AUTOSAR XML (schema 4-2-2)
package /ComponentTypes
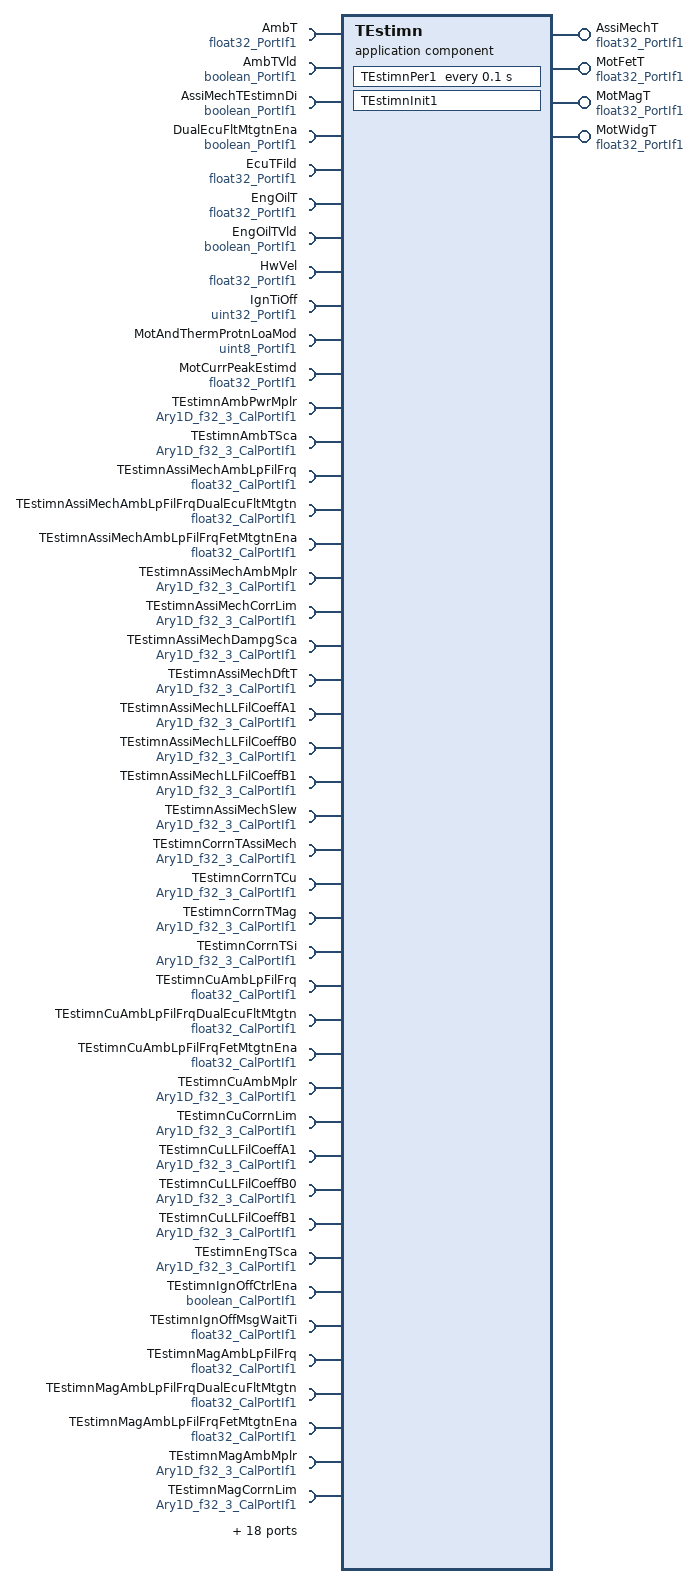
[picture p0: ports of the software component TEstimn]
  application sw component type TEstimn
    4 x provide port, all with nonqueued-sender-com-spec{data-element=Val, init-value=25}, provided-interface=float32_PortIf1:
      AssiMechT
      MotFetT
      MotMagT
      MotWidgT
    62 x require port:
      AmbT: nonqueued-receiver-com-spec{data-element=Val, filter=data-filter-type=ALWAYS, init-value=0}, required-interface=float32_PortIf1
      AmbTVld: nonqueued-receiver-com-spec{data-element=Logl, filter=data-filter-type=ALWAYS, init-value=0}, required-interface=boolean_PortIf1
      AssiMechTEstimnDi: nonqueued-receiver-com-spec{data-element=Logl, filter=data-filter-type=ALWAYS, init-value=0}, required-interface=boolean_PortIf1
      DualEcuFltMtgtnEna: nonqueued-receiver-com-spec{data-element=Logl, filter=data-filter-type=ALWAYS, init-value=0}, required-interface=boolean_PortIf1
      EcuTFild: nonqueued-receiver-com-spec{data-element=Val, filter=data-filter-type=ALWAYS, init-value=25}, required-interface=float32_PortIf1
      EngOilT: nonqueued-receiver-com-spec{data-element=Val, filter=data-filter-type=ALWAYS, init-value=0}, required-interface=float32_PortIf1
      EngOilTVld: nonqueued-receiver-com-spec{data-element=Logl, filter=data-filter-type=ALWAYS, init-value=0}, required-interface=boolean_PortIf1
      HwVel: nonqueued-receiver-com-spec{data-element=Val, filter=data-filter-type=ALWAYS, init-value=0}, required-interface=float32_PortIf1
      IgnTiOff: nonqueued-receiver-com-spec{data-element=Val, filter=data-filter-type=ALWAYS, init-value=0}, required-interface=uint32_PortIf1
      MotAndThermProtnLoaMod: nonqueued-receiver-com-spec{data-element=Val, filter=data-filter-type=ALWAYS, init-value=0}, required-interface=uint8_PortIf1
      MotCurrPeakEstimd: nonqueued-receiver-com-spec{data-element=Val, filter=data-filter-type=ALWAYS, init-value=0}, required-interface=float32_PortIf1
      TEstimnAmbPwrMplr: parameter-require-com-spec{init-value=[0.01, 0.01, 0.01], parameter=Ary1D}, required-interface=Ary1D_f32_3_CalPortIf1
      TEstimnAmbTSca: parameter-require-com-spec{init-value=[0.9, 0.9, 0.9], parameter=Ary1D}, required-interface=Ary1D_f32_3_CalPortIf1
      TEstimnAssiMechAmbLpFilFrq: parameter-require-com-spec{init-value=0.024, parameter=Val}, required-interface=float32_CalPortIf1
      TEstimnAssiMechAmbLpFilFrqDualEcuFltMtgtn: parameter-require-com-spec{init-value=0.024, parameter=Val}, required-interface=float32_CalPortIf1
      TEstimnAssiMechAmbLpFilFrqFetMtgtnEna: parameter-require-com-spec{init-value=0.024, parameter=Val}, required-interface=float32_CalPortIf1
      TEstimnAssiMechAmbMplr: parameter-require-com-spec{init-value=[0.01, 0.01, 0.01], parameter=Ary1D}, required-interface=Ary1D_f32_3_CalPortIf1
      TEstimnAssiMechCorrLim: parameter-require-com-spec{init-value=[60, 60, 60], parameter=Ary1D}, required-interface=Ary1D_f32_3_CalPortIf1
      TEstimnAssiMechDampgSca: parameter-require-com-spec{init-value=[0.0001, 0.0001, 0.0001], parameter=Ary1D}, required-interface=Ary1D_f32_3_CalPortIf1
      TEstimnAssiMechDftT: parameter-require-com-spec{init-value=[50, 50, 50], parameter=Ary1D}, required-interface=Ary1D_f32_3_CalPortIf1
      TEstimnAssiMechLLFilCoeffA1: parameter-require-com-spec{init-value=[0.99996858, 0.99996858, 0.99996858], parameter=Ary1D}, required-interface=Ary1D_f32_3_CalPortIf1
      TEstimnAssiMechLLFilCoeffB0: parameter-require-com-spec{init-value=[0.4761987, 0.4761987, 0.4761987], parameter=Ary1D}, required-interface=Ary1D_f32_3_CalPortIf1
      TEstimnAssiMechLLFilCoeffB1: parameter-require-com-spec{init-value=[-0.4761673, -0.4761673, -0.4761673], parameter=Ary1D}, required-interface=Ary1D_f32_3_CalPortIf1
      TEstimnAssiMechSlew: parameter-require-com-spec{init-value=[1, 1, 1], parameter=Ary1D}, required-interface=Ary1D_f32_3_CalPortIf1
      TEstimnCorrnTAssiMech: parameter-require-com-spec{init-value=[0, 0, 0], parameter=Ary1D}, required-interface=Ary1D_f32_3_CalPortIf1
      TEstimnCorrnTCu: parameter-require-com-spec{init-value=[0, 0, 0], parameter=Ary1D}, required-interface=Ary1D_f32_3_CalPortIf1
      TEstimnCorrnTMag: parameter-require-com-spec{init-value=[0, 0, 0], parameter=Ary1D}, required-interface=Ary1D_f32_3_CalPortIf1
      TEstimnCorrnTSi: parameter-require-com-spec{init-value=[0, 0, 0], parameter=Ary1D}, required-interface=Ary1D_f32_3_CalPortIf1
      TEstimnCuAmbLpFilFrq: parameter-require-com-spec{init-value=0.024, parameter=Val}, required-interface=float32_CalPortIf1
      TEstimnCuAmbLpFilFrqDualEcuFltMtgtn: parameter-require-com-spec{init-value=0.024, parameter=Val}, required-interface=float32_CalPortIf1
      TEstimnCuAmbLpFilFrqFetMtgtnEna: parameter-require-com-spec{init-value=0.024, parameter=Val}, required-interface=float32_CalPortIf1
      TEstimnCuAmbMplr: parameter-require-com-spec{init-value=[0.75, 0.75, 0.75], parameter=Ary1D}, required-interface=Ary1D_f32_3_CalPortIf1
      TEstimnCuCorrnLim: parameter-require-com-spec{init-value=[80, 80, 80], parameter=Ary1D}, required-interface=Ary1D_f32_3_CalPortIf1
      TEstimnCuLLFilCoeffA1: parameter-require-com-spec{init-value=[0.999943, 0.999943, 0.999943], parameter=Ary1D}, required-interface=Ary1D_f32_3_CalPortIf1
      TEstimnCuLLFilCoeffB0: parameter-require-com-spec{init-value=[0.86667, 0.86667, 0.86667], parameter=Ary1D}, required-interface=Ary1D_f32_3_CalPortIf1
      TEstimnCuLLFilCoeffB1: parameter-require-com-spec{init-value=[-0.866613, -0.866613, -0.866613], parameter=Ary1D}, required-interface=Ary1D_f32_3_CalPortIf1
      TEstimnEngTSca: parameter-require-com-spec{init-value=[0.1, 0.1, 0.1], parameter=Ary1D}, required-interface=Ary1D_f32_3_CalPortIf1
      TEstimnIgnOffCtrlEna: parameter-require-com-spec{init-value=0, parameter=Logl}, required-interface=boolean_CalPortIf1
      TEstimnIgnOffMsgWaitTi: parameter-require-com-spec{init-value=0.5, parameter=Val}, required-interface=float32_CalPortIf1
      TEstimnMagAmbLpFilFrq: parameter-require-com-spec{init-value=0.024, parameter=Val}, required-interface=float32_CalPortIf1
      TEstimnMagAmbLpFilFrqDualEcuFltMtgtn: parameter-require-com-spec{init-value=0.024, parameter=Val}, required-interface=float32_CalPortIf1
      TEstimnMagAmbLpFilFrqFetMtgtnEna: parameter-require-com-spec{init-value=0.024, parameter=Val}, required-interface=float32_CalPortIf1
      TEstimnMagAmbMplr: parameter-require-com-spec{init-value=[0.01, 0.01, 0.01], parameter=Ary1D}, required-interface=Ary1D_f32_3_CalPortIf1
      TEstimnMagCorrnLim: parameter-require-com-spec{init-value=[60, 60, 60], parameter=Ary1D}, required-interface=Ary1D_f32_3_CalPortIf1
      TEstimnMagLLFilCoeffA1: parameter-require-com-spec{init-value=[0.999962, 0.999962, 0.999962], parameter=Ary1D}, required-interface=Ary1D_f32_3_CalPortIf1
      TEstimnMagLLFilCoeffB0: parameter-require-com-spec{init-value=[0.571437, 0.571437, 0.571437], parameter=Ary1D}, required-interface=Ary1D_f32_3_CalPortIf1
      TEstimnMagLLFilCoeffB1: parameter-require-com-spec{init-value=[-0.571399, -0.571399, -0.571399], parameter=Ary1D}, required-interface=Ary1D_f32_3_CalPortIf1
      TEstimnSiAmbLpFilFrq: parameter-require-com-spec{init-value=0.024, parameter=Val}, required-interface=float32_CalPortIf1
      TEstimnSiAmbLpFilFrqDualEcuFltMtgtn: parameter-require-com-spec{init-value=0.024, parameter=Val}, required-interface=float32_CalPortIf1
      TEstimnSiAmbLpFilFrqFetMtgtnEna: parameter-require-com-spec{init-value=0.024, parameter=Val}, required-interface=float32_CalPortIf1
      TEstimnSiAmbMplr: parameter-require-com-spec{init-value=[0, 0, 0], parameter=Ary1D}, required-interface=Ary1D_f32_3_CalPortIf1
      TEstimnSiCorrnLim: parameter-require-com-spec{init-value=[60, 60, 60], parameter=Ary1D}, required-interface=Ary1D_f32_3_CalPortIf1
      TEstimnSiLLFilCoeffA1: parameter-require-com-spec{init-value=[0.999889, 0.999889, 0.999889], parameter=Ary1D}, required-interface=Ary1D_f32_3_CalPortIf1
      TEstimnSiLLFilCoeffB0: parameter-require-com-spec{init-value=[1.68568, 1.68568, 1.68568], parameter=Ary1D}, required-interface=Ary1D_f32_3_CalPortIf1
      TEstimnSiLLFilCoeffB1: parameter-require-com-spec{init-value=[-1.68556, -1.68556, -1.68556], parameter=Ary1D}, required-interface=Ary1D_f32_3_CalPortIf1
      TEstimnTauAssiMech: parameter-require-com-spec{init-value=[4000, 4000, 4000], parameter=Ary1D}, required-interface=Ary1D_f32_3_CalPortIf1
      TEstimnTauCu: parameter-require-com-spec{init-value=[79, 79, 79], parameter=Ary1D}, required-interface=Ary1D_f32_3_CalPortIf1
      TEstimnTauMag: parameter-require-com-spec{init-value=[50, 50, 50], parameter=Ary1D}, required-interface=Ary1D_f32_3_CalPortIf1
      TEstimnTauSi: parameter-require-com-spec{init-value=[214, 214, 214], parameter=Ary1D}, required-interface=Ary1D_f32_3_CalPortIf1
      TEstimnWghtAvrgTDi: parameter-require-com-spec{init-value=[0, 0, 0], parameter=Ary1D}, required-interface=Ary1D_logl_3_CalPortIf1
      TFilStVal: required-com-specs=[EraseBlock, GetErrorStatus, InvalidateNvBlock, ReadBlock, SetRamBlockStatus, WriteBlock], required-interface=NvMService_AC3_SRBS
      VehTiVld: nonqueued-receiver-com-spec{data-element=Logl, filter=data-filter-type=ALWAYS, init-value=0}, required-interface=boolean_PortIf1
    behavior TEstimn_InternalBehavior
      ar-typed-per-instance-memorys:
        36 x data, all with sw-calibration-access=READ-ONLY:
          AmbTVldPrev: type=boolean
          AssiMechFilLp: type=FilLpRec1
          AssiMechTEstimnPrev: type=float32
          AssiMechTInitEna: type=boolean
          AssiMechTSlewLimPrev: type=float32
          CuFilLp: type=FilLpRec1
          CuTEstimnPrev: type=float32
          dTEstimnAmbPwr: type=float32
          dTEstimnAssiMechCorrn: type=float32
          dTEstimnAssiMechDampgSca: type=float32
          dTEstimnAssiMechFil: type=float32
          dTEstimnCuCorrn: type=float32
          dTEstimnMagCorrn: type=float32
          dTEstimnScadAmbT: type=float32
          dTEstimnScadEngT: type=float32
          dTEstimnSiCorrn: type=float32
          dTEstimnWghtAvrgT: type=float32
          DualEcuFltMtgtnPrev: type=boolean
          EngOilTVldPrev: type=boolean
          FetMtgtnEnaPrev: type=boolean
          FilAssiMechLLValPwrUp: type=float32
          FilAssiMechLpValPwrUp: type=float32
          FilCuLLValPwrUp: type=float32
          FilCuLpValPwrUp: type=float32
          FilMagLLValPwrUp: type=float32
          FilMagLpValPwrUp: type=float32
          FilSiLLValPwrUp: type=float32
          FilSiLpValPwrUp: type=float32
          MagFilLp: type=FilLpRec1
          MagTEstimnPrev: type=float32
          RepInitCntrFlg: type=boolean
          RepInitCntrVal: type=float32
          SiFilLp: type=FilLpRec1
          SiTEstimnPrev: type=float32
          TEstimnFltMtgtnCalIdx: type=uint8
          TFilStVal: type=TFilStValRec1
      init event TEstimn_InitEvent: start-on-event=TEstimnInit1
      timing event TMT_TEstimnPer1: start-on-event=TEstimnPer1, period=0.1
      explicit-inter-runnable-variables:
        data FilStVariRepInitFlg: type=boolean, init-value=0
      runnable TEstimnInit1
        data-receive-point-by-arguments:
          9 x access:
            REC_AmbT_Val: accessed-variable=AmbT.Val
            REC_AmbTVld_Logl: accessed-variable=AmbTVld.Logl
            REC_DualEcuFltMtgtnEna_Logl: accessed-variable=DualEcuFltMtgtnEna.Logl
            REC_EcuTFild_Val: accessed-variable=EcuTFild.Val
            REC_EngOilT_Val: accessed-variable=EngOilT.Val
            REC_EngOilTVld_Logl: accessed-variable=EngOilTVld.Logl
            REC_IgnTiOff_Val: accessed-variable=IgnTiOff.Val
            REC_MotAndThermProtnLoaMod_Val: accessed-variable=MotAndThermProtnLoaMod.Val
            REC_VehTiVld_Logl: accessed-variable=VehTiVld.Logl
        data-send-points:
          4 x access:
            SEND_AssiMechT_Val: accessed-variable=AssiMechT.Val
            SEND_MotFetT_Val: accessed-variable=MotFetT.Val
            SEND_MotMagT_Val: accessed-variable=MotMagT.Val
            SEND_MotWidgT_Val: accessed-variable=MotWidgT.Val
        sync call SC_TFilStVal_GetErrorStatus: operation=TFilStVal.GetErrorStatus, timeout=0
        sync call SC_TFilStVal_SetRamBlockStatus: operation=TFilStVal.SetRamBlockStatus, timeout=0
        written-local-variables:
          access WRITE_FilStVariRepInitFlg: accessed-variable=FilStVariRepInitFlg
      runnable TEstimnPer1
        data-receive-point-by-arguments:
          12 x access:
            REC_AmbT_Val: accessed-variable=AmbT.Val
            REC_AmbTVld_Logl: accessed-variable=AmbTVld.Logl
            REC_AssiMechTEstimnDi_Logl: accessed-variable=AssiMechTEstimnDi.Logl
            REC_DualEcuFltMtgtnEna_Logl: accessed-variable=DualEcuFltMtgtnEna.Logl
            REC_EcuTFild_Val: accessed-variable=EcuTFild.Val
            REC_EngOilT_Val: accessed-variable=EngOilT.Val
            REC_EngOilTVld_Logl: accessed-variable=EngOilTVld.Logl
            REC_HwVel_Val: accessed-variable=HwVel.Val
            REC_IgnTiOff_Val: accessed-variable=IgnTiOff.Val
            REC_MotAndThermProtnLoaMod_Val: accessed-variable=MotAndThermProtnLoaMod.Val
            REC_MotCurrPeakEstimd_Val: accessed-variable=MotCurrPeakEstimd.Val
            REC_VehTiVld_Logl: accessed-variable=VehTiVld.Logl
        data-send-points:
          4 x access:
            SEND_AssiMechT_Val: accessed-variable=AssiMechT.Val
            SEND_MotFetT_Val: accessed-variable=MotFetT.Val
            SEND_MotMagT_Val: accessed-variable=MotMagT.Val
            SEND_MotWidgT_Val: accessed-variable=MotWidgT.Val
        read-local-variables:
          access READ_FilStVariRepInitFlg: accessed-variable=FilStVariRepInitFlg
        sync call SC_TFilStVal_SetRamBlockStatus: operation=TFilStVal.SetRamBlockStatus, timeout=0
      swc service dependency NvmTFilStVal: assigned-datas=role-based-data-assignment={role=ramBlock, used-data-element=TFilStVal}, assigned-ports=role-based-port-assignment={port-prototype=TFilStVal, role=NvMService_AC3_SRBS}
        service-needs:
          nv block needs NvmTFilStVal: n-data-sets=0, ram-block-status-control=API, reliability=ERROR-DETECTION, resistant-to-changed-sw=true, restore-at-start=true, store-at-shutdown=true
  swc implementation TEstimn_Implementation: behavior=TEstimn_InternalBehavior
    code-descriptors:
      code Default: artifact-descriptors=autosar-engineering-object={short-label=Default, category=SWSRC}
